# R9A09G057H register map
Vendor: Renesas Electronics; File version: 1.0
Registers are 32-bit, read-write, no defined reset value unless marked. A register's access mark holds for its fields unless they carry their own. Offsets are from the block's base; [hi:lo] are bit positions; lines under a group give offsets from that group; {n}, {i} and the like mark numbered series; 'fields as' and 'values as' point back to an identical list.

## R_CANFD — IO define file for canfd.
Base 0x12440000
{0x0+0x10*i} CFDC[{i}] (i=0..5) group — CFDC register group
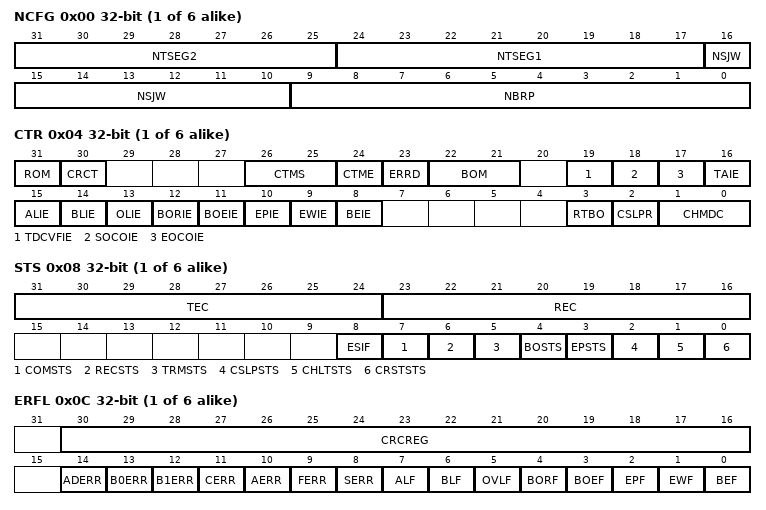
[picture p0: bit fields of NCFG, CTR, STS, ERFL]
  0x00 NCFG
    [31:25] NTSEG2, [24:17] NTSEG1, [16:10] NSJW, [9:0] NBRP
  0x04 CTR
    [31] ROM, [30] CRCT, [26:25] CTMS, [24] CTME, [23] ERRD, [22:21] BOM, [19] TDCVFIE, [18] SOCOIE, [17] EOCOIE, [16] TAIE, [15] ALIE, [14] BLIE, [13] OLIE, [12] BORIE, [11] BOEIE, [10] EPIE, [9] EWIE, [8] BEIE, [3] RTBO, [2] CSLPR, [1:0] CHMDC
  0x08 STS
    [31:24] TEC, [23:16] REC ro, [8] ESIF, [7] COMSTS ro, [6] RECSTS ro, [5] TRMSTS ro, [4] BOSTS ro, [3] EPSTS ro, [2] CSLPSTS ro, [1] CHLTSTS ro, [0] CRSTSTS ro
  0x0C ERFL
    [30:16] CRCREG ro, [14] ADERR, [13] B0ERR, [12] B1ERR, [11] CERR, [10] AERR, [9] FERR, [8] SERR, [7] ALF, [6] BLF, [5] OVLF, [4] BORF, [3] BOEF, [2] EPF, [1] EWF, [0] BEF
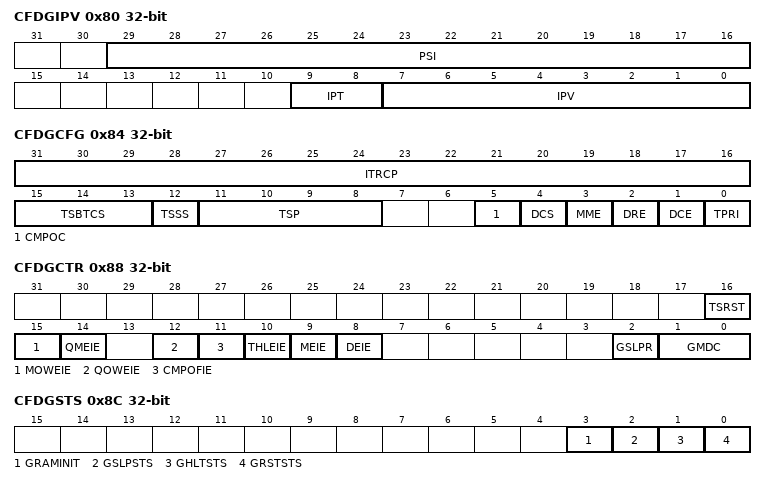
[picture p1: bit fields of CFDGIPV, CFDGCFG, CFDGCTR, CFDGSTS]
0x80 CFDGIPV ro
  [29:16] PSI rw, [9:8] IPT rw, [7:0] IPV rw
0x84 CFDGCFG
  [31:16] ITRCP, [15:13] TSBTCS, [12] TSSS, [11:8] TSP, [5] CMPOC, [4] DCS, [3] MME, [2] DRE, [1] DCE, [0] TPRI
0x88 CFDGCTR
  [16] TSRST, [15] MOWEIE, [14] QMEIE, [12] QOWEIE, [11] CMPOFIE, [10] THLEIE, [9] MEIE, [8] DEIE, [2] GSLPR, [1:0] GMDC
0x8C CFDGSTS
  [3] GRAMINIT ro, [2] GSLPSTS ro, [1] GHLTSTS ro, [0] GRSTSTS ro
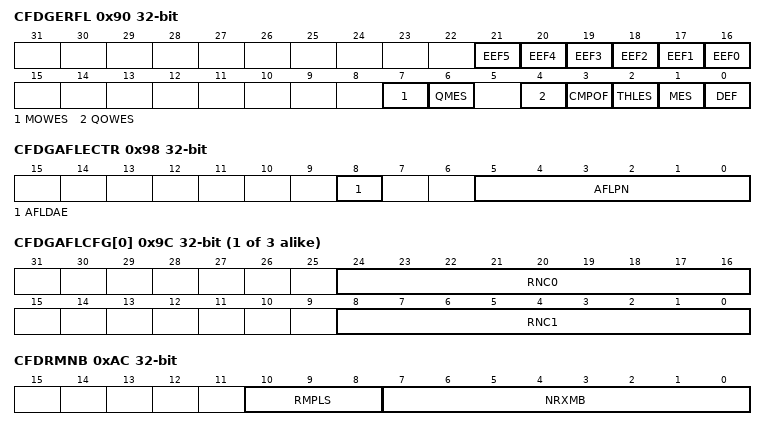
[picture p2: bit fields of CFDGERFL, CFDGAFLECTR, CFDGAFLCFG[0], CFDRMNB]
0x90 CFDGERFL
  [n+16] EEF{n} (n=0..5), [7] MOWES ro, [6] QMES ro, [4] QOWES ro, [3] CMPOF, [2] THLES ro, [1] MES ro, [0] DEF
0x94 CFDGTSC
  [15:0] TS ro
0x98 CFDGAFLECTR
  [8] AFLDAE, [5:0] AFLPN
{0x9C+4i} CFDGAFLCFG[{i}] (i=0..2)
  [24:16] RNC0, [8:0] RNC1
0xAC CFDRMNB
  [10:8] RMPLS, [7:0] NRXMB
{0xB0+4i} CFDRMND[{i}] (i=0..2)
  [31:0] RMNS
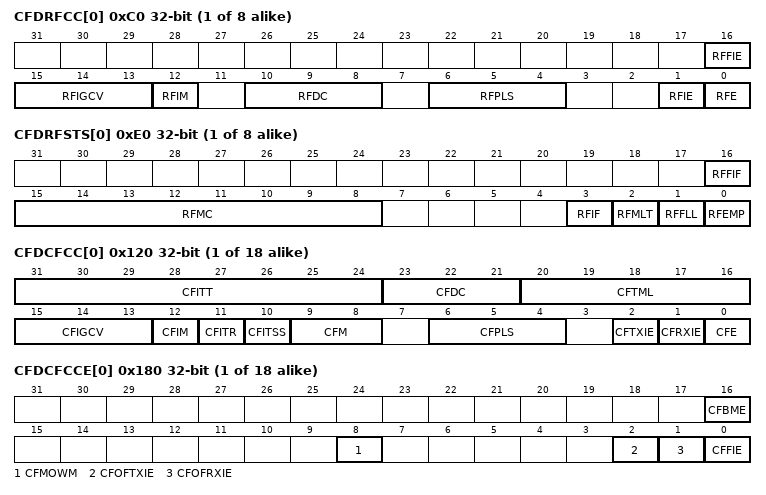
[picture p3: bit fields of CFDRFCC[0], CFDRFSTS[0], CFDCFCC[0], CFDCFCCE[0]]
{0xC0+4i} CFDRFCC[{i}] (i=0..7)
  [16] RFFIE, [15:13] RFIGCV, [12] RFIM, [10:8] RFDC, [6:4] RFPLS, [1] RFIE, [0] RFE
{0xE0+4i} CFDRFSTS[{i}] (i=0..7)
  [16] RFFIF, [15:8] RFMC ro, [3] RFIF, [2] RFMLT, [1] RFFLL ro, [0] RFEMP ro
{0x100+4i} CFDRFPCTR[{i}] (i=0..7)
  [7:0] RFPC wo
{0x120+4i} CFDCFCC[{i}] (i=0..17)
  [31:24] CFITT, [23:21] CFDC, [20:16] CFTML, [15:13] CFIGCV, [12] CFIM, [11] CFITR, [10] CFITSS, [9:8] CFM, [6:4] CFPLS, [2] CFTXIE, [1] CFRXIE, [0] CFE
{0x180+4i} CFDCFCCE[{i}] (i=0..17)
  [16] CFBME, [8] CFMOWM, [2] CFOFTXIE, [1] CFOFRXIE, [0] CFFIE
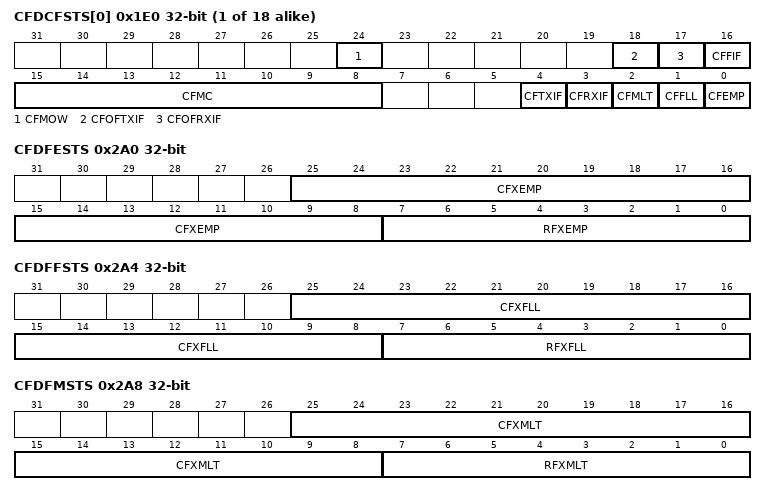
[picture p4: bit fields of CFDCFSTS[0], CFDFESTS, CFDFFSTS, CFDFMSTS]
{0x1E0+4i} CFDCFSTS[{i}] (i=0..17)
  [24] CFMOW, [18] CFOFTXIF, [17] CFOFRXIF, [16] CFFIF, [15:8] CFMC ro, [4] CFTXIF, [3] CFRXIF, [2] CFMLT, [1] CFFLL ro, [0] CFEMP ro
{0x240+4i} CFDCFPCTR[{i}] (i=0..17)
  [7:0] CFPC wo
0x2A0 CFDFESTS ro
  [25:8] CFXEMP, [7:0] RFXEMP
0x2A4 CFDFFSTS ro
  [25:8] CFXFLL, [7:0] RFXFLL
0x2A8 CFDFMSTS ro
  [25:8] CFXMLT, [7:0] RFXMLT
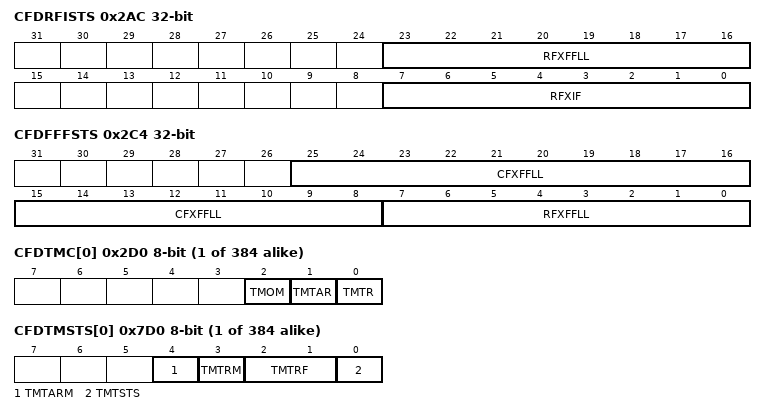
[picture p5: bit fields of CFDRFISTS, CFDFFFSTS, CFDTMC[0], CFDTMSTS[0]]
0x2AC CFDRFISTS
  [23:16] RFXFFLL ro, [7:0] RFXIF ro
0x2B0 CFDCFRISTS
  [17:0] CFXRXIF ro
0x2B4 CFDCFTISTS
  [17:0] CFXTXIF ro
0x2B8 CFDCFOFRISTS ro
  [17:0] CFXOFRXIF
0x2BC CFDCFOFTISTS ro
  [17:0] CFXOFTXIF
0x2C0 CFDCFMOWSTS ro
  [17:0] CFXMOW
0x2C4 CFDFFFSTS ro
  [25:8] CFXFFLL, [7:0] RFXFFLL
{0x2D0+i} CFDTMC[{i}] (i=0..383) 8-bit
  [2] TMOM, [1] TMTAR, [0] TMTR
{0x7D0+i} CFDTMSTS[{i}] (i=0..383) 8-bit
  [4] TMTARM ro, [3] TMTRM ro, [2:1] TMTRF, [0] TMTSTS ro
{0xCD0+4i} CFDTMTRSTS[{i}] (i=0..11) ro
  [15:0] TMTRSTS
{0xD70+4i} CFDTMTARSTS[{i}] (i=0..11) ro
  [15:0] TMTARSTS
{0xE10+4i} CFDTMTCSTS[{i}] (i=0..11) ro
  [15:0] TMTCSTS
{0xEB0+4i} CFDTMTASTS[{i}] (i=0..11) ro
  [15:0] TMTASTS
{0xF50+4i} CFDTMIEC[{i}] (i=0..11)
  [15:0] TMIE
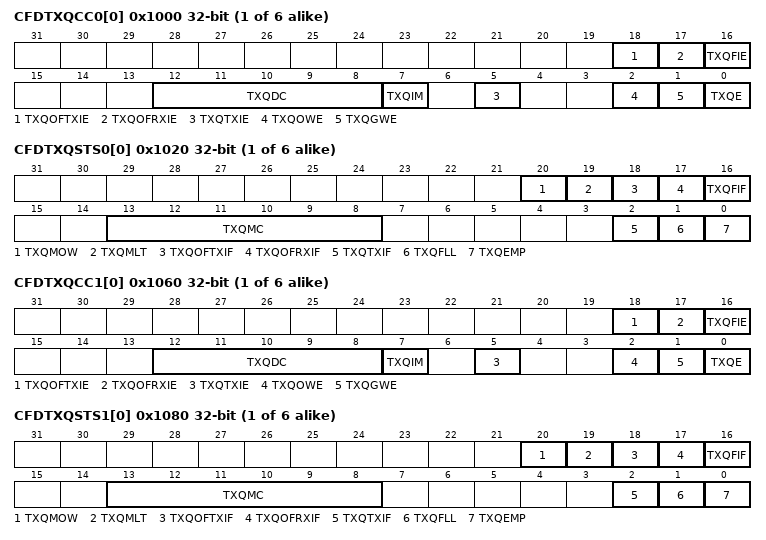
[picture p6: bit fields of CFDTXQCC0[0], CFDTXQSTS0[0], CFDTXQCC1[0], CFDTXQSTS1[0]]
{0x1000+4i} CFDTXQCC0[{i}] (i=0..5)
  [18] TXQOFTXIE, [17] TXQOFRXIE, [16] TXQFIE, [12:8] TXQDC, [7] TXQIM, [5] TXQTXIE, [2] TXQOWE, [1] TXQGWE, [0] TXQE
{0x1020+4i} CFDTXQSTS0[{i}] (i=0..5)
  [20] TXQMOW, [19] TXQMLT, [18] TXQOFTXIF, [17] TXQOFRXIF, [16] TXQFIF, [13:8] TXQMC ro, [2] TXQTXIF, [1] TXQFLL ro, [0] TXQEMP ro
{0x1040+4i} CFDTXQPCTR0[{i}] (i=0..5)
  [7:0] TXQPC wo
{0x1060+4i} CFDTXQCC1[{i}] (i=0..5)
  fields as CFDTXQCC0[0]
{0x1080+4i} CFDTXQSTS1[{i}] (i=0..5)
  fields as CFDTXQSTS0[0]
{0x10A0+4i} CFDTXQPCTR1[{i}] (i=0..5)
  [7:0] TXQPC wo
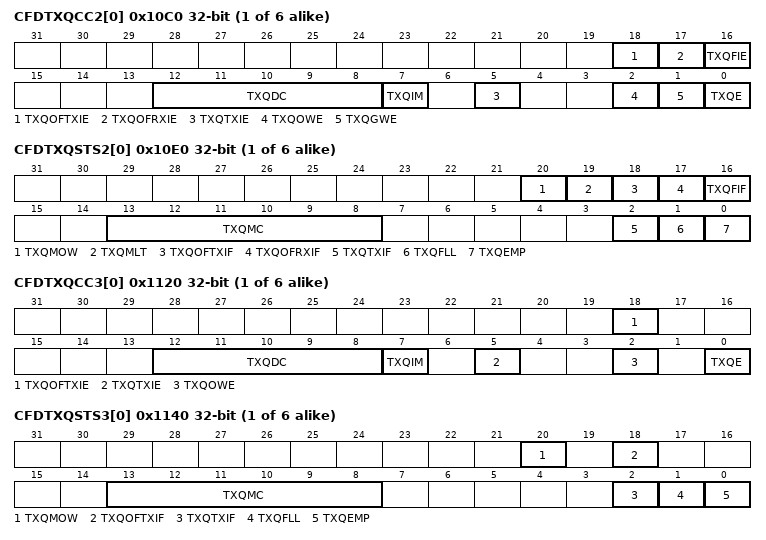
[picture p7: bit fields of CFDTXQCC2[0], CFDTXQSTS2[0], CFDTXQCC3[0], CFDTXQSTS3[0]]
{0x10C0+4i} CFDTXQCC2[{i}] (i=0..5)
  fields as CFDTXQCC0[0]
{0x10E0+4i} CFDTXQSTS2[{i}] (i=0..5)
  fields as CFDTXQSTS0[0]
{0x1100+4i} CFDTXQPCTR2[{i}] (i=0..5)
  [7:0] TXQPC wo
{0x1120+4i} CFDTXQCC3[{i}] (i=0..5)
  [18] TXQOFTXIE, [12:8] TXQDC, [7] TXQIM, [5] TXQTXIE, [2] TXQOWE, [0] TXQE
{0x1140+4i} CFDTXQSTS3[{i}] (i=0..5)
  [20] TXQMOW, [18] TXQOFTXIF, [13:8] TXQMC ro, [2] TXQTXIF, [1] TXQFLL ro, [0] TXQEMP ro
{0x1160+4i} CFDTXQPCTR3[{i}] (i=0..5)
  [7:0] TXQPC wo
0x1180 CFDTXQESTS ro
  [23:0] TXQxEMP
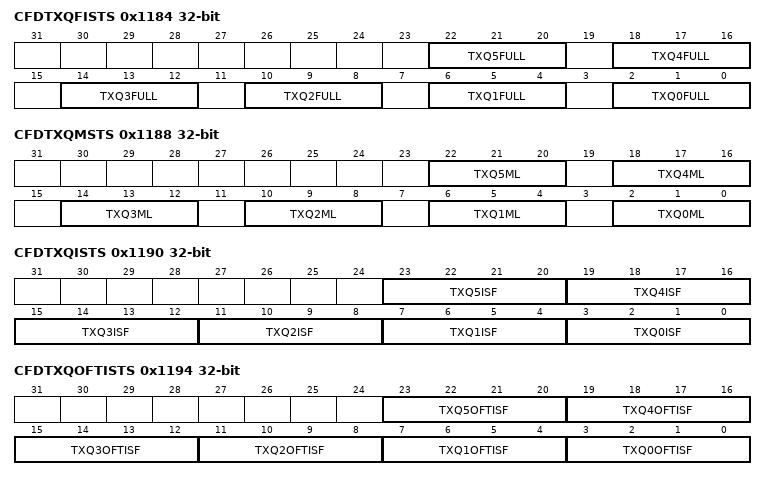
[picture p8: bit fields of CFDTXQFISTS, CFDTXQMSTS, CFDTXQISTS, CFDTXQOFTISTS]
0x1184 CFDTXQFISTS
  [4n+2:4n] TXQ{n}FULL ro (n=0..5)
0x1188 CFDTXQMSTS
  [4n+2:4n] TXQ{n}ML ro (n=0..5)
0x1190 CFDTXQISTS
  [4n+3:4n] TXQ{n}ISF ro (n=0..5)
0x1194 CFDTXQOFTISTS
  [4n+3:4n] TXQ{n}OFTISF ro (n=0..5)
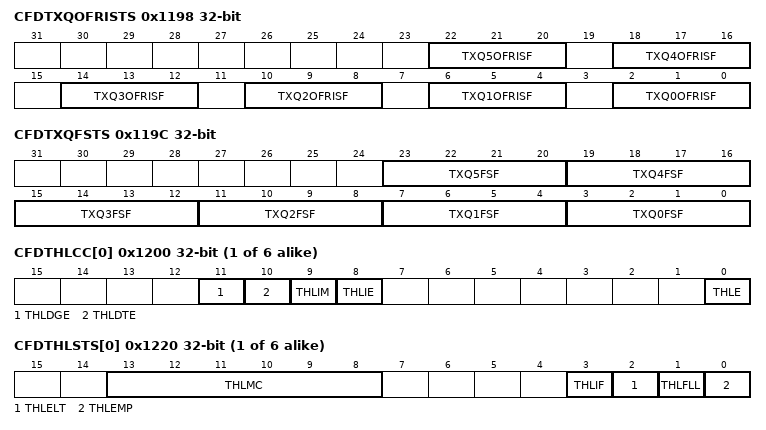
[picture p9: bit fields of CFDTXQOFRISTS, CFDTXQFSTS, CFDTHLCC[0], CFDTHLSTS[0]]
0x1198 CFDTXQOFRISTS
  [4n+2:4n] TXQ{n}OFRISF ro (n=0..5)
0x119C CFDTXQFSTS ro
  [4n+3:4n] TXQ{n}FSF (n=0..5)
{0x1200+4i} CFDTHLCC[{i}] (i=0..5)
  [11] THLDGE, [10] THLDTE, [9] THLIM, [8] THLIE, [0] THLE
{0x1220+4i} CFDTHLSTS[{i}] (i=0..5)
  [13:8] THLMC ro, [3] THLIF, [2] THLELT, [1] THLFLL ro, [0] THLEMP ro
{0x1240+4i} CFDTHLPCTR[{i}] (i=0..5)
  [7:0] THLPC wo
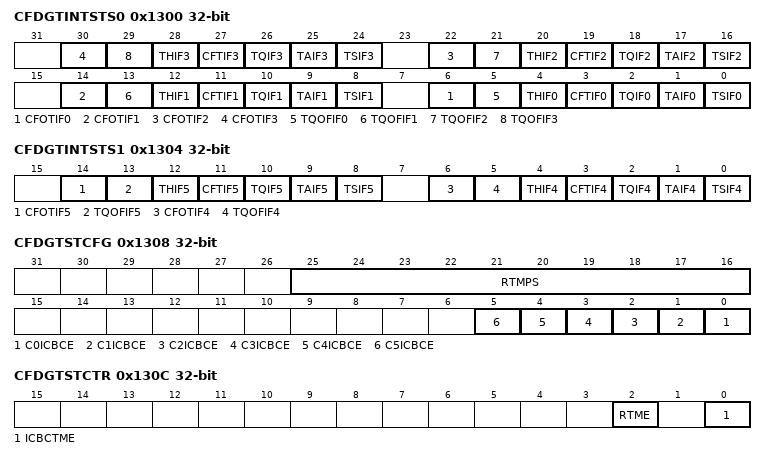
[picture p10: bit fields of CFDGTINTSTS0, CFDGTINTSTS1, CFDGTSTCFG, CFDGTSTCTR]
0x1300 CFDGTINTSTS0
  [8n+6] CFOTIF{n} ro (n=0..3), [8n+5] TQOFIF{n} ro (n=0..3), [8n+4] THIF{n} ro (n=0..3), [8n+3] CFTIF{n} ro (n=0..3), [8n+2] TQIF{n} ro (n=0..3), [8n+1] TAIF{n} ro (n=0..3), [8n] TSIF{n} ro (n=0..3)
0x1304 CFDGTINTSTS1
  [14] CFOTIF5 ro, [13] TQOFIF5 ro, [12] THIF5 ro, [11] CFTIF5 ro, [10] TQIF5 ro, [9] TAIF5 ro, [8] TSIF5 ro, [6] CFOTIF4 ro, [5] TQOFIF4 ro, [4] THIF4 ro, [3] CFTIF4 ro, [2] TQIF4 ro, [1] TAIF4 ro, [0] TSIF4 ro
0x1308 CFDGTSTCFG
  [25:16] RTMPS, [n] C{n}ICBCE (n=0..5)
0x130C CFDGTSTCTR
  [2] RTME, [0] ICBCTME
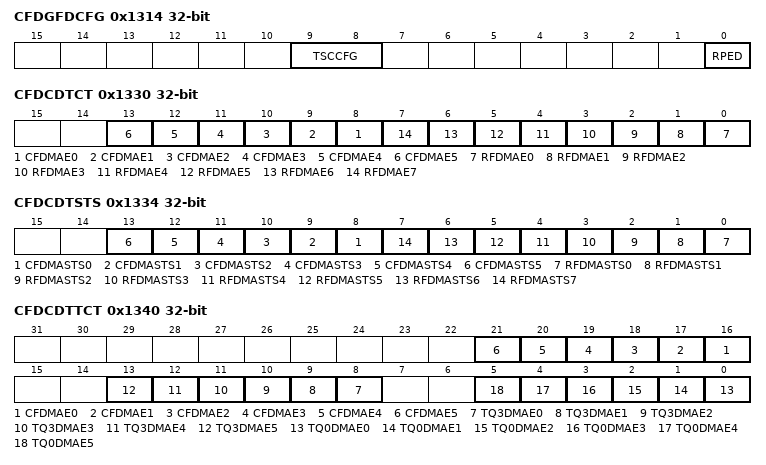
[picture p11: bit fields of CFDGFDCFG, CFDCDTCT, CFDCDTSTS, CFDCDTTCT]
0x1314 CFDGFDCFG
  [9:8] TSCCFG, [0] RPED
0x131C CFDGLOCKK
  [15:0] LOCK wo
0x1330 CFDCDTCT
  [n+8] CFDMAE{n} (n=0..5), [n] RFDMAE{n} (n=0..7)
0x1334 CFDCDTSTS ro
  [n+8] CFDMASTS{n} (n=0..5), [n] RFDMASTS{n} (n=0..7)
0x1340 CFDCDTTCT
  [n+16] CFDMAE{n} (n=0..5), [n+8] TQ3DMAE{n} (n=0..5), [n] TQ0DMAE{n} (n=0..5)
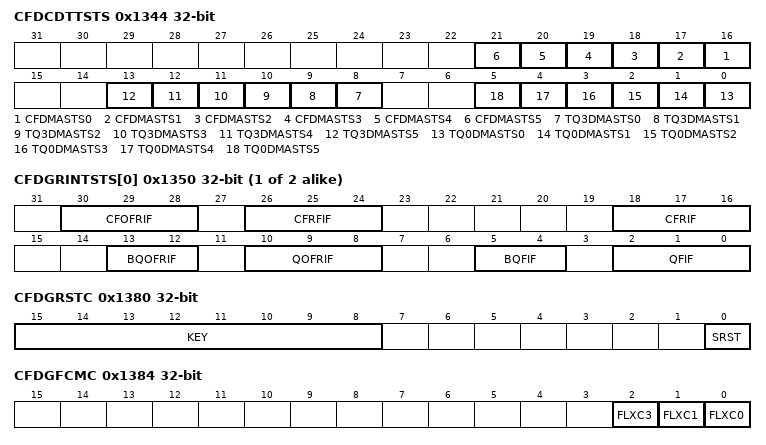
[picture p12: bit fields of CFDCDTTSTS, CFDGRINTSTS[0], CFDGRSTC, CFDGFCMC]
0x1344 CFDCDTTSTS
  [n+16] CFDMASTS{n} ro (n=0..5), [n+8] TQ3DMASTS{n} ro (n=0..5), [n] TQ0DMASTS{n} ro (n=0..5)
{0x1350+4i} CFDGRINTSTS[{i}] (i=0..1)
  [30:28] CFOFRIF ro, [26:24] CFRFIF ro, [18:16] CFRIF ro, [13:12] BQOFRIF ro, [10:8] QOFRIF ro, [5:4] BQFIF ro, [2:0] QFIF ro
0x1380 CFDGRSTC
  [15:8] KEY wo, [0] SRST
0x1384 CFDGFCMC
  [2] FLXC3, [1] FLXC1, [0] FLXC0
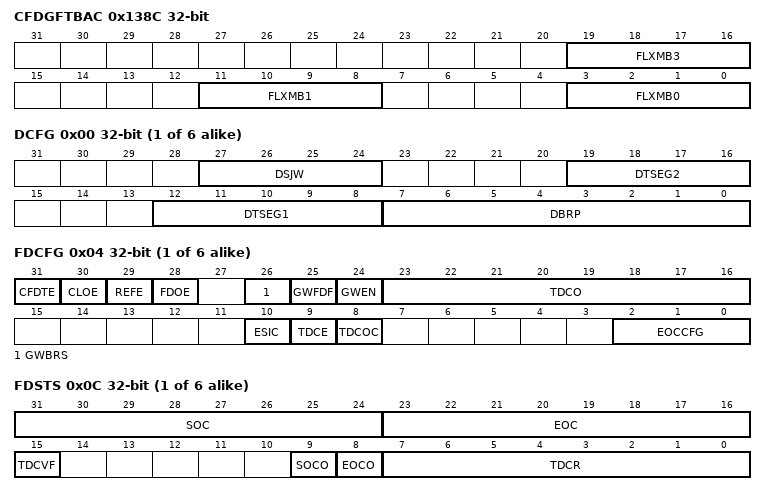
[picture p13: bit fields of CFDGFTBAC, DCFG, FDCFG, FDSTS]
0x138C CFDGFTBAC
  [19:16] FLXMB3, [11:8] FLXMB1, [3:0] FLXMB0
{0x1400+0x20*i} CFDC2[{i}] (i=0..5) group — CFDC2 register group
  0x00 DCFG
    [27:24] DSJW, [19:16] DTSEG2, [12:8] DTSEG1, [7:0] DBRP
  0x04 FDCFG
    [31] CFDTE, [30] CLOE, [29] REFE, [28] FDOE, [26] GWBRS, [25] GWFDF, [24] GWEN, [23:16] TDCO, [10] ESIC, [9] TDCE, [8] TDCOC, [2:0] EOCCFG
  0x08 FDCTR
    [1] SOCCLR, [0] EOCCLR
  0x0C FDSTS
    [31:24] SOC ro, [23:16] EOC ro, [15] TDCVF, [9] SOCO, [8] EOCO, [7:0] TDCR ro
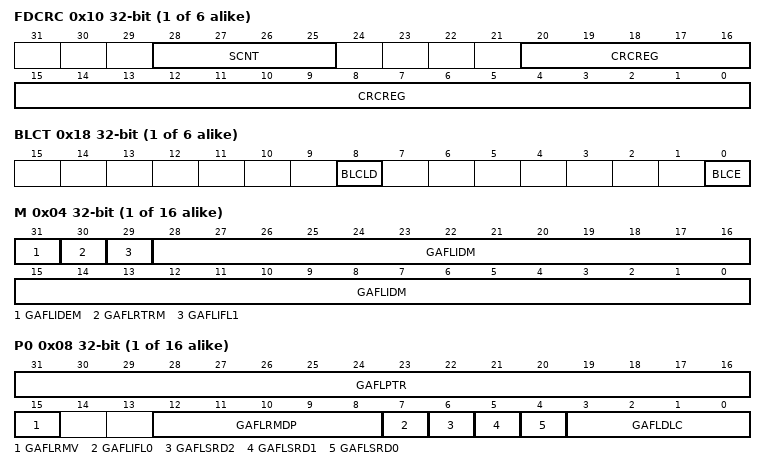
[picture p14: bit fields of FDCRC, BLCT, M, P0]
  0x10 FDCRC
    [28:25] SCNT ro, [20:0] CRCREG ro
  0x18 BLCT
    [8] BLCLD wo, [0] BLCE
  0x1C BLSTS
    [31:3] BLC ro
{0x1800+0x10*i} CFDGAFL[{i}] (i=0..15) group — CFDGAFL register group
  0x00 ID
    [31] GAFLIDE, [30] GAFLRTR, [29] GAFLLB, [28:0] GAFLID
  0x04 M
    [31] GAFLIDEM, [30] GAFLRTRM, [29] GAFLIFL1, [28:0] GAFLIDM
  0x08 P0
    [31:16] GAFLPTR, [15] GAFLRMV, [12:8] GAFLRMDP, [7] GAFLIFL0, [6] GAFLSRD2, [5] GAFLSRD1, [4] GAFLSRD0, [3:0] GAFLDLC
  0x0C P1
    [25:0] GAFLFDP
{0x2000+0x80*i} CFDRM[{i}] (i=0..95) group — CFDRM register group
  0x00 ID ro
    [31] RMIDE, [30] RMRTR, [28:0] RMID
  0x04 PTR ro
    [31:28] RMDLC, [15:0] RMTS
  0x08 FDSTS ro
    [31:16] RMPTR, [9:8] RMIFL, [2] RMFDF, [1] RMBRS, [0] RMESI
  {0xC+j} DF[{j}] (j=0..63) 8-bit ro
    [7:0] RMDB
{0x6000+0x80*i} CFDRF[{i}] (i=0..7) group — CFDRF register group
  0x00 ID ro
    [31] RFIDE, [30] RFRTR, [28:0] RFID
  0x04 PTR ro
    [31:28] RFDLC, [15:0] RFTS
  0x08 FDSTS ro
    [31:16] RFPTR, [9:8] RFIFL, [2] RFFDF, [1] RFBRS, [0] RFESI
  {0xC+j} DF[{j}] (j=0..63) 8-bit ro
    [7:0] RFDB
{0x6400+0x80*i} CFDCF[{i}] (i=0..17) group — CFDCF register group
  0x00 ID
    [31] CFIDE, [30] CFRTR, [29] THLEN, [28:0] CFID
  0x04 PTR
    [31:28] CFDLC, [15:0] CFTS
  0x08 FDSTS
    [31:16] CFPTR, [9:8] CFIFL, [2] CFFDF, [1] CFBRS, [0] CFESI
  {0xC+j} DF[{j}] (j=0..63) 8-bit
    [7:0] CFDB
{0x8000+8i} CFDTHL[{i}] (i=0..1) group — CFDTHL register group
  0x00 ACC0 ro
    [31:16] TMTS, [15] TGW, [9:3] BN, [2:0] BT
  0x04 ACC1
    [17:16] TIFL ro, [15:0] TID ro
{0x8400+4i} CFDRPGACC[{i}] (i=0..63)
  [31:0] RDTA
{0x10000+0x80*i} CFDTM[{i}] (i=0..383) group — CFDTM register group
  0x00 ID
    [31] TMIDE, [30] TMRTR, [29] THLEN, [28:0] TMID
  0x04 PTR
    [31:28] TMDLC
  0x08 FDCTR
    [31:16] TMPTR, [9:8] TMIFL, [2] TMFDF, [1] TMBRS, [0] TMESI
  {0xC+j} DF[{j}] (j=0..63) 8-bit
    [7:0] TMDB
